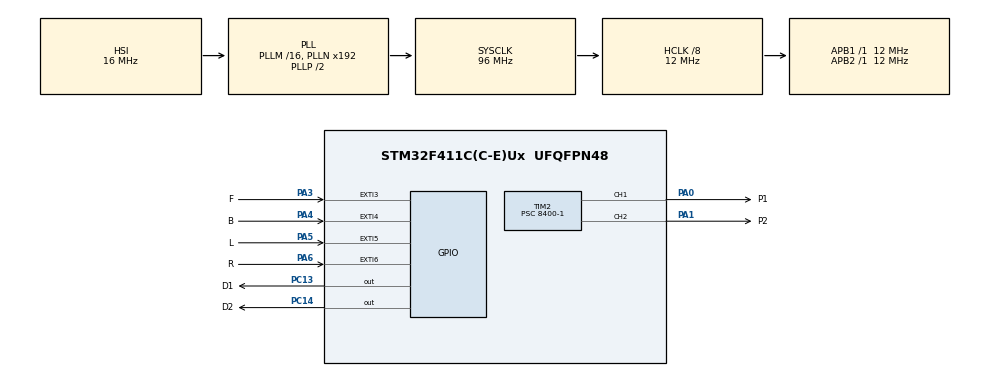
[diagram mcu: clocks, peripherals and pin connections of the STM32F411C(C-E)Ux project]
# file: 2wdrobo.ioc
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Mcu.Family=STM32F4
Mcu.Name=STM32F411C(C-E)Ux
Mcu.Package=UFQFPN48
NVIC.EXTI3_IRQn=true\:0\:0\:false\:false\:true\:true\:true\:true
NVIC.EXTI4_IRQn=true\:0\:0\:false\:false\:true\:true\:true\:true
NVIC.EXTI9_5_IRQn=true\:0\:0\:false\:false\:true\:true\:true\:true
NVIC.PriorityGroup=NVIC_PRIORITYGROUP_4
NVIC.TIM2_IRQn=true\:0\:0\:false\:false\:true\:true\:true\:true
PA0-WKUP.GPIO_Label=P1
PA0-WKUP.Signal=S_TIM2_CH1_ETR
PA1.GPIO_Label=P2
PA1.Signal=S_TIM2_CH2
PA13.Mode=Serial_Wire
PA13.Signal=SYS_JTMS-SWDIO
PA14.Mode=Serial_Wire
PA14.Signal=SYS_JTCK-SWCLK
PA3.GPIO_Label=F
PA3.GPIO_ModeDefaultEXTI=GPIO_MODE_IT_FALLING
PA3.GPIO_PuPd=GPIO_PULLUP
PA3.Signal=GPXTI3
PA4.GPIO_Label=B
PA4.GPIO_ModeDefaultEXTI=GPIO_MODE_IT_FALLING
PA4.GPIO_PuPd=GPIO_PULLUP
PA4.Signal=GPXTI4
PA5.GPIO_Label=L
PA5.GPIO_ModeDefaultEXTI=GPIO_MODE_IT_FALLING
PA5.GPIO_PuPd=GPIO_PULLUP
PA5.Signal=GPXTI5
PA6.GPIO_Label=R
PA6.GPIO_ModeDefaultEXTI=GPIO_MODE_IT_FALLING
PA6.GPIO_PuPd=GPIO_PULLUP
PA6.Signal=GPXTI6
PC13-ANTI_TAMP.GPIO_Label=D1
PC13-ANTI_TAMP.PinState=GPIO_PIN_SET
PC13-ANTI_TAMP.Signal=GPIO_Output
PC14-OSC32_IN.GPIO_Label=D2
PC14-OSC32_IN.PinState=GPIO_PIN_SET
PC14-OSC32_IN.Signal=GPIO_Output
PH0\ -\ OSC_IN.Mode=HSE-External-Oscillator
PH0\ -\ OSC_IN.Signal=RCC_OSC_IN
PH1\ -\ OSC_OUT.Mode=HSE-External-Oscillator
PH1\ -\ OSC_OUT.Signal=RCC_OSC_OUT
ProjectManager.HeapSize=0x200
ProjectManager.StackSize=0x400
ProjectManager.TargetToolchain=STM32CubeIDE
RCC.AHBCLKDivider=RCC_SYSCLK_DIV8
RCC.AHBFreq_Value=12000000
RCC.APB1Freq_Value=12000000
RCC.APB1TimFreq_Value=12000000
RCC.APB2Freq_Value=12000000
RCC.APB2TimFreq_Value=12000000
RCC.CortexFreq_Value=12000000
RCC.HCLKFreq_Value=12000000
RCC.HSE_VALUE=25000000
RCC.HSI_VALUE=16000000
RCC.LSE_VALUE=32768
RCC.SYSCLKFreq_VALUE=96000000
RCC.SYSCLKSource=RCC_SYSCLKSOURCE_PLLCLK
RCC.VCOOutputFreq_Value=192000000
SH.S_TIM2_CH1_ETR.0=TIM2_CH1,PWM Generation1 CH1
SH.S_TIM2_CH2.0=TIM2_CH2,PWM Generation2 CH2
TIM2.AutoReloadPreload=TIM_AUTORELOAD_PRELOAD_ENABLE
TIM2.Channel-PWM\ Generation1\ CH1=TIM_CHANNEL_1
TIM2.Channel-PWM\ Generation2\ CH2=TIM_CHANNEL_2
TIM2.Period=10-1
TIM2.Prescaler=8400-1
TIM2.Pulse-PWM\ Generation1\ CH1=500
TIM2.Pulse-PWM\ Generation2\ CH2=500
VP_TIM2_VS_ClockSourceINT.Mode=Internal
board=custom

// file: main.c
/* USER CODE BEGIN Header */
/**
  ******************************************************************************
  * @file           : main.c
  * @brief          : Main program body
  ******************************************************************************
  * @attention
  *
  * Copyright (c) 2022 STMicroelectronics.
  * All rights reserved.
  *
  * This software is licensed under terms that can be found in the LICENSE file
  * in the root directory of this software component.
  * If no LICENSE file comes with this software, it is provided AS-IS.
  *
  ******************************************************************************
  */
/* USER CODE END Header */
#include "main.h"

_TIM_HandleTypeDef htim2;

void SystemClock_Config(void);
static void MX_GPIO_Init(void);
static void MX_TIM2_Init(void);

/* USER CODE BEGIN 0 */
void HAL_GPIO_EXTI_Callback(uint16_t GPIO_Pin){
	switch(GPIO_Pin){
	case F_Pin:
		    DIR = 1;
		    break;
	case B_Pin:
			DIR = 2;
			break;
	default:
			DIR = 0;
			break;
	}

}

/* USER CODE END 0 */

int main(void)
{

  /* MCU Configuration--------------------------------------------------------*/

  /* Reset of all peripherals, Initializes the Flash interface and the Systick. */
  HAL_Init();

  /* Configure the system clock */
  SystemClock_Config();

  /* Initialize all configured peripherals */
  MX_GPIO_Init();
  MX_TIM2_Init();
  /* USER CODE BEGIN 2 */
  HAL_TIM_PWM_Start_IT(&htim2,TIM_CHANNEL_1);
   HAL_TIM_PWM_Start_IT(&htim2,TIM_CHANNEL_2);

  /* USER CODE END 2 */

  /* Infinite loop */
  while (1)
  {
	  switch(DIR){
	 	  case 0: //Stop
	 			HAL_GPIO_WritePin(D1_GPIO_Port, D1_Pin, GPIO_PIN_SET);
	 			HAL_GPIO_WritePin(D2_GPIO_Port, D2_Pin, GPIO_PIN_SET);

	 			TIM2->CCR1 = 0; TIM2->CCR2 = 0;
	 			break;
	 	  case 1: //Forward
	 	  			HAL_GPIO_WritePin(D1_GPIO_Port, D1_Pin, GPIO_PIN_SET);
	 	  			HAL_GPIO_WritePin(D2_GPIO_Port, D2_Pin, GPIO_PIN_SET);

	 	  			TIM2->CCR1 = 500; TIM2->CCR2 = 500;
	 	  			break;
	 	  default: //Stop
	 	  	  			HAL_GPIO_WritePin(D1_GPIO_Port, D1_Pin, GPIO_PIN_SET);
	 	  	  			HAL_GPIO_WritePin(D2_GPIO_Port, D2_Pin, GPIO_PIN_SET);

	 	  	  			TIM2->CCR1 = 0; TIM2->CCR2 = 0;
	 	  	  			break;

	 	  }

  }
}

void SystemClock_Config(void)
{
  RCC_OscInitTypeDef RCC_OscInitStruct = {0};
  RCC_ClkInitTypeDef RCC_ClkInitStruct = {0};

  /** Configure the main internal regulator output voltage
  */
  __HAL_RCC_PWR_CLK_ENABLE();
  __HAL_PWR_VOLTAGESCALING_CONFIG(PWR_REGULATOR_VOLTAGE_SCALE1);

  /** Initializes the RCC Oscillators according to the specified parameters
  * in the RCC_OscInitTypeDef structure.
  */
  RCC_OscInitStruct.OscillatorType = RCC_OSCILLATORTYPE_HSI;
  RCC_OscInitStruct.HSIState = RCC_HSI_ON;
  RCC_OscInitStruct.HSICalibrationValue = RCC_HSICALIBRATION_DEFAULT;
  RCC_OscInitStruct.PLL.PLLState = RCC_PLL_ON;
  RCC_OscInitStruct.PLL.PLLSource = RCC_PLLSOURCE_HSI;
  RCC_OscInitStruct.PLL.PLLM = 16;
  RCC_OscInitStruct.PLL.PLLN = 192;
  RCC_OscInitStruct.PLL.PLLP = RCC_PLLP_DIV2;
  RCC_OscInitStruct.PLL.PLLQ = 4;
  if (HAL_RCC_OscConfig(&RCC_OscInitStruct) != HAL_OK)
  {
    Error_Handler();
  }

  /** Initializes the CPU, AHB and APB buses clocks
  */
  RCC_ClkInitStruct.ClockType = RCC_CLOCKTYPE_HCLK|RCC_CLOCKTYPE_SYSCLK
                              |RCC_CLOCKTYPE_PCLK1|RCC_CLOCKTYPE_PCLK2;
  RCC_ClkInitStruct.SYSCLKSource = RCC_SYSCLKSOURCE_PLLCLK;
  RCC_ClkInitStruct.AHBCLKDivider = RCC_SYSCLK_DIV8;
  RCC_ClkInitStruct.APB1CLKDivider = RCC_HCLK_DIV1;
  RCC_ClkInitStruct.APB2CLKDivider = RCC_HCLK_DIV1;

  if (HAL_RCC_ClockConfig(&RCC_ClkInitStruct, FLASH_LATENCY_0) != HAL_OK)
  {
    Error_Handler();
  }
}

static void MX_TIM2_Init(void)
{

  TIM_ClockConfigTypeDef sClockSourceConfig = {0};
  TIM_MasterConfigTypeDef sMasterConfig = {0};
  TIM_OC_InitTypeDef sConfigOC = {0};

  htim2.Instance = TIM2;
  htim2.Init.Prescaler = 8400-1;
  htim2.Init.CounterMode = TIM_COUNTERMODE_UP;
  htim2.Init.Period = 10-1;
  htim2.Init.ClockDivision = TIM_CLOCKDIVISION_DIV1;
  htim2.Init.AutoReloadPreload = TIM_AUTORELOAD_PRELOAD_ENABLE;
  if (HAL_TIM_Base_Init(&htim2) != HAL_OK)
  {
    Error_Handler();
  }
  sClockSourceConfig.ClockSource = TIM_CLOCKSOURCE_INTERNAL;
  if (HAL_TIM_ConfigClockSource(&htim2, &sClockSourceConfig) != HAL_OK)
  {
    Error_Handler();
  }
  if (HAL_TIM_PWM_Init(&htim2) != HAL_OK)
  {
    Error_Handler();
  }
  sMasterConfig.MasterOutputTrigger = TIM_TRGO_RESET;
  sMasterConfig.MasterSlaveMode = TIM_MASTERSLAVEMODE_DISABLE;
  if (HAL_TIMEx_MasterConfigSynchronization(&htim2, &sMasterConfig) != HAL_OK)
  {
    Error_Handler();
  }
  sConfigOC.OCMode = TIM_OCMODE_PWM1;
  sConfigOC.Pulse = 500;
  sConfigOC.OCPolarity = TIM_OCPOLARITY_HIGH;
  sConfigOC.OCFastMode = TIM_OCFAST_DISABLE;
  if (HAL_TIM_PWM_ConfigChannel(&htim2, &sConfigOC, TIM_CHANNEL_1) != HAL_OK)
  {
    Error_Handler();
  }
  if (HAL_TIM_PWM_ConfigChannel(&htim2, &sConfigOC, TIM_CHANNEL_2) != HAL_OK)
  {
    Error_Handler();
  }
  HAL_TIM_MspPostInit(&htim2);

}

static void MX_GPIO_Init(void)
{
  GPIO_InitTypeDef GPIO_InitStruct = {0};

  /* GPIO Ports Clock Enable */
  __HAL_RCC_GPIOC_CLK_ENABLE();
  __HAL_RCC_GPIOH_CLK_ENABLE();
  __HAL_RCC_GPIOA_CLK_ENABLE();

  /*Configure GPIO pin Output Level */
  HAL_GPIO_WritePin(GPIOC, D1_Pin|D2_Pin, GPIO_PIN_SET);

  /*Configure GPIO pins : D1_Pin D2_Pin */
  GPIO_InitStruct.Pin = D1_Pin|D2_Pin;
  GPIO_InitStruct.Mode = GPIO_MODE_OUTPUT_PP;
  GPIO_InitStruct.Pull = GPIO_NOPULL;
  GPIO_InitStruct.Speed = GPIO_SPEED_FREQ_LOW;
  HAL_GPIO_Init(GPIOC, &GPIO_InitStruct);

  /*Configure GPIO pins : F_Pin B_Pin L_Pin R_Pin */
  GPIO_InitStruct.Pin = F_Pin|B_Pin|L_Pin|R_Pin;
  GPIO_InitStruct.Mode = GPIO_MODE_IT_FALLING;
  GPIO_InitStruct.Pull = GPIO_PULLUP;
  HAL_GPIO_Init(GPIOA, &GPIO_InitStruct);

  /* EXTI interrupt init*/
  HAL_NVIC_SetPriority(EXTI3_IRQn, 0, 0);
  HAL_NVIC_EnableIRQ(EXTI3_IRQn);

  HAL_NVIC_SetPriority(EXTI4_IRQn, 0, 0);
  HAL_NVIC_EnableIRQ(EXTI4_IRQn);

  HAL_NVIC_SetPriority(EXTI9_5_IRQn, 0, 0);
  HAL_NVIC_EnableIRQ(EXTI9_5_IRQn);

}

void Error_Handler(void)
{
  __disable_irq();
  while (1)
  {
  }
}
